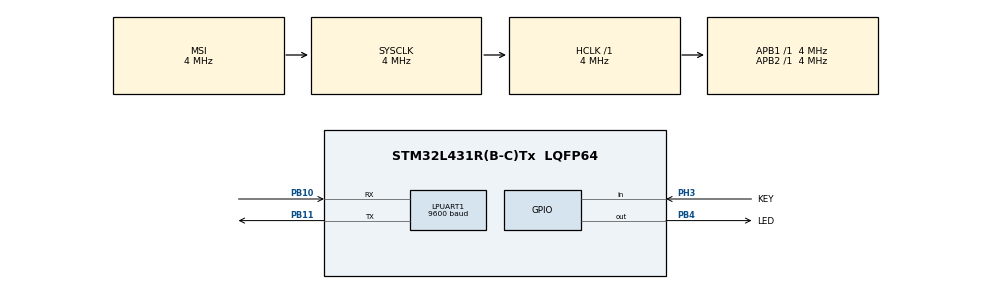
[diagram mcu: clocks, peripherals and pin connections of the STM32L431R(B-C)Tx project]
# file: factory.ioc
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CRC.InputDataFormat=CRC_INPUTDATA_FORMAT_BYTES
Dma.LPUART_RX.0.Direction=DMA_PERIPH_TO_MEMORY
Dma.LPUART_RX.0.Instance=DMA2_Channel7
Dma.LPUART_RX.0.MemDataAlignment=DMA_MDATAALIGN_BYTE
Dma.LPUART_RX.0.MemInc=DMA_MINC_ENABLE
Dma.LPUART_RX.0.Mode=DMA_CIRCULAR
Dma.LPUART_RX.0.PeriphDataAlignment=DMA_PDATAALIGN_BYTE
Dma.LPUART_RX.0.PeriphInc=DMA_PINC_DISABLE
Dma.LPUART_RX.0.Priority=DMA_PRIORITY_LOW
Dma.LPUART_TX.1.Direction=DMA_MEMORY_TO_PERIPH
Dma.LPUART_TX.1.Instance=DMA2_Channel6
Dma.LPUART_TX.1.MemDataAlignment=DMA_MDATAALIGN_BYTE
Dma.LPUART_TX.1.MemInc=DMA_MINC_ENABLE
Dma.LPUART_TX.1.Mode=DMA_NORMAL
Dma.LPUART_TX.1.PeriphDataAlignment=DMA_PDATAALIGN_BYTE
Dma.LPUART_TX.1.PeriphInc=DMA_PINC_DISABLE
Dma.LPUART_TX.1.Priority=DMA_PRIORITY_LOW
Dma.Request0=LPUART_RX
Dma.Request1=LPUART_TX
IWDG.Prescaler=IWDG_PRESCALER_64
IWDG.Reload=2500
IWDG.Window=2500
LPUART1.BaudRate=9600
LPUART1.WordLength=UART_WORDLENGTH_8B
Mcu.Family=STM32L4
Mcu.Name=STM32L431R(B-C)Tx
Mcu.Package=LQFP64
NVIC.DMA2_Channel6_IRQn=true\:8\:0\:true\:false\:true\:false\:true\:true
NVIC.DMA2_Channel7_IRQn=true\:7\:0\:true\:false\:true\:false\:true\:true
NVIC.LPUART1_IRQn=true\:6\:0\:true\:false\:true\:true\:true\:true
NVIC.PriorityGroup=NVIC_PRIORITYGROUP_4
PA13\ (JTMS-SWDIO).Mode=Serial_Wire
PA13\ (JTMS-SWDIO).Signal=SYS_JTMS-SWDIO
PA14\ (JTCK-SWCLK).Mode=Serial_Wire
PA14\ (JTCK-SWCLK).Signal=SYS_JTCK-SWCLK
PB10.GPIO_Speed=GPIO_SPEED_FREQ_LOW
PB10.Mode=Asynchronous
PB10.Signal=LPUART1_RX
PB11.GPIO_Speed=GPIO_SPEED_FREQ_LOW
PB11.Mode=Asynchronous
PB11.Signal=LPUART1_TX
PB4\ (NJTRST).GPIO_Label=LED
PB4\ (NJTRST).GPIO_PuPd=GPIO_PULLUP
PB4\ (NJTRST).Signal=GPIO_Output
PC14-OSC32_IN\ (PC14).Mode=LSE-External-Oscillator
PC14-OSC32_IN\ (PC14).Signal=RCC_OSC32_IN
PC15-OSC32_OUT\ (PC15).Mode=LSE-External-Oscillator
PC15-OSC32_OUT\ (PC15).Signal=RCC_OSC32_OUT
PH3-BOOT0.GPIO_Label=KEY
PH3-BOOT0.GPIO_PuPd=GPIO_NOPULL
PH3-BOOT0.Signal=GPIO_Input
ProjectManager.HeapSize=0x400
ProjectManager.StackSize=0x800
ProjectManager.TargetToolchain=Makefile
RCC.ADCFreq_Value=16000000
RCC.AHBFreq_Value=4000000
RCC.APB1Freq_Value=4000000
RCC.APB1TimFreq_Value=4000000
RCC.APB2Freq_Value=4000000
RCC.APB2TimFreq_Value=4000000
RCC.CortexFreq_Value=4000000
RCC.HCLKFreq_Value=4000000
RCC.HSE_VALUE=8000000
RCC.HSI48_VALUE=48000000
RCC.HSI_VALUE=16000000
RCC.LPUART1CLockSelection=RCC_LPUART1CLKSOURCE_LSE
RCC.MSI_VALUE=4000000
RCC.RTCClockSelection=RCC_RTCCLKSOURCE_LSE
RCC.SYSCLKFreq_VALUE=4000000
RCC.VCOOutputFreq_Value=32000000
VP_CRC_VS_CRC.Mode=CRC_Activate
VP_IWDG_VS_IWDG.Mode=IWDG_Activate
board=custom

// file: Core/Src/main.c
/* USER CODE BEGIN Header */
/**
  ******************************************************************************
  * @file           : main.c
  * @brief          : Main program body
  ******************************************************************************
  * @attention
  *
  * Copyright (c) 2023 STMicroelectronics.
  * All rights reserved.
  *
  * This software is licensed under terms that can be found in the LICENSE file
  * in the root directory of this software component.
  * If no LICENSE file comes with this software, it is provided AS-IS.
  *
  ******************************************************************************
  */
/* USER CODE END Header */
#include "main.h"
#include "crc.h"
#include "dma.h"
#include "iwdg.h"
#include "usart.h"
#include "gpio.h"

/* USER CODE BEGIN Includes */
#include "device.h"
#include "update.h"
#include "tasks.h"
/* USER CODE END Includes */

void SystemClock_Config(void);

int main(void)
{
  /* USER CODE BEGIN 1 */
  SCB->VTOR = ADDR_BASE_FACTORY;
  /* USER CODE END 1 */

  /* MCU Configuration--------------------------------------------------------*/

  /* Reset of all peripherals, Initializes the Flash interface and the Systick. */
  HAL_Init();

  /* Configure the system clock */
  SystemClock_Config();

  /* Initialize all configured peripherals */
  MX_GPIO_Init();
  MX_DMA_Init();
  MX_IWDG_Init();
  MX_LPUART1_UART_Init();
  MX_CRC_Init();
  /* USER CODE BEGIN 2 */
  uart_config();
  boot_param_check_upgrade();
  tasks_init();
  frame_parse_register(FRAME_TYPE_BEGIN, iap_update);
  frame_parse_register(FRAME_TYPE_END, iap_update);
  frame_parse_register(FRAME_TYPE_DATA, iap_update);
  frame_parse_register(FRAME_TYPE_DEBUG, print_frame);
  LL_IWDG_ReloadCounter(IWDG);
  /* USER CODE END 2 */

  /* Infinite loop */
  /* USER CODE BEGIN WHILE */
  while (1)
  {
    uart_frame_parse();
    /* USER CODE END WHILE */

    /* USER CODE BEGIN 3 */
    tasks_poll();
  }
  /* USER CODE END 3 */
}

void SystemClock_Config(void)
{
  RCC_OscInitTypeDef RCC_OscInitStruct = {0};
  RCC_ClkInitTypeDef RCC_ClkInitStruct = {0};

  /** Configure the main internal regulator output voltage
  */
  if (HAL_PWREx_ControlVoltageScaling(PWR_REGULATOR_VOLTAGE_SCALE1) != HAL_OK)
  {
    Error_Handler();
  }

  /** Configure LSE Drive Capability
  */
  HAL_PWR_EnableBkUpAccess();
  __HAL_RCC_LSEDRIVE_CONFIG(RCC_LSEDRIVE_LOW);

  /** Initializes the RCC Oscillators according to the specified parameters
  * in the RCC_OscInitTypeDef structure.
  */
  RCC_OscInitStruct.OscillatorType = RCC_OSCILLATORTYPE_LSI|RCC_OSCILLATORTYPE_LSE
                              |RCC_OSCILLATORTYPE_MSI;
  RCC_OscInitStruct.LSEState = RCC_LSE_ON;
  RCC_OscInitStruct.LSIState = RCC_LSI_ON;
  RCC_OscInitStruct.MSIState = RCC_MSI_ON;
  RCC_OscInitStruct.MSICalibrationValue = 0;
  RCC_OscInitStruct.MSIClockRange = RCC_MSIRANGE_6;
  RCC_OscInitStruct.PLL.PLLState = RCC_PLL_NONE;
  if (HAL_RCC_OscConfig(&RCC_OscInitStruct) != HAL_OK)
  {
    Error_Handler();
  }

  /** Initializes the CPU, AHB and APB buses clocks
  */
  RCC_ClkInitStruct.ClockType = RCC_CLOCKTYPE_HCLK|RCC_CLOCKTYPE_SYSCLK
                              |RCC_CLOCKTYPE_PCLK1|RCC_CLOCKTYPE_PCLK2;
  RCC_ClkInitStruct.SYSCLKSource = RCC_SYSCLKSOURCE_MSI;
  RCC_ClkInitStruct.AHBCLKDivider = RCC_SYSCLK_DIV1;
  RCC_ClkInitStruct.APB1CLKDivider = RCC_HCLK_DIV1;
  RCC_ClkInitStruct.APB2CLKDivider = RCC_HCLK_DIV1;

  if (HAL_RCC_ClockConfig(&RCC_ClkInitStruct, FLASH_LATENCY_0) != HAL_OK)
  {
    Error_Handler();
  }

  /** Enable MSI Auto calibration
  */
  HAL_RCCEx_EnableMSIPLLMode();
}

void Error_Handler(void)
{
  __disable_irq();
  while (1)
  {
  }
}
